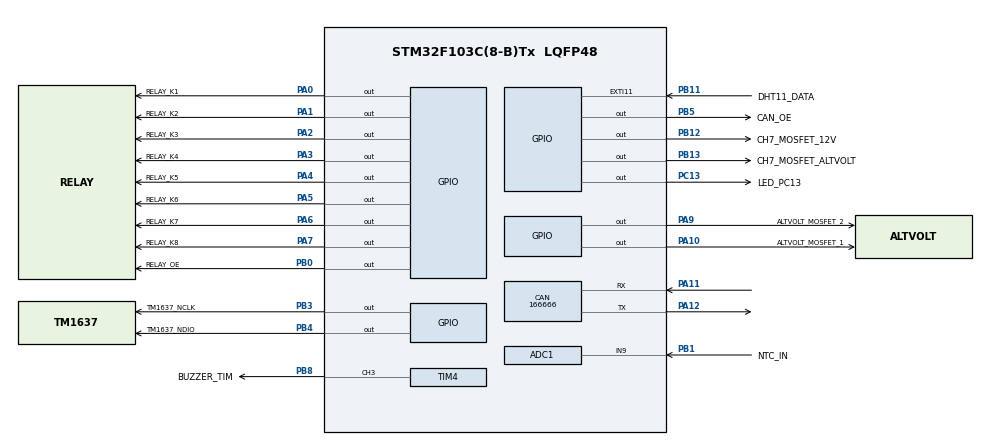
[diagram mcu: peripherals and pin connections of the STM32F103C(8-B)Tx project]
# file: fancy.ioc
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ADC1.Channel-0\#ChannelRegularConversion=ADC_CHANNEL_9
ADC1.Channel-1\#ChannelRegularConversion=ADC_CHANNEL_TEMPSENSOR
ADC1.Channel-3\#ChannelRegularConversion=ADC_CHANNEL_VREFINT
ADC1.NbrOfConversion=3
ADC1.NbrOfConversionFlag=1
ADC1.Rank-0\#ChannelRegularConversion=1
ADC1.Rank-1\#ChannelRegularConversion=2
ADC1.Rank-3\#ChannelRegularConversion=3
ADC1.SamplingTime-0\#ChannelRegularConversion=ADC_SAMPLETIME_13CYCLES_5
ADC1.SamplingTime-1\#ChannelRegularConversion=ADC_SAMPLETIME_13CYCLES_5
ADC1.SamplingTime-3\#ChannelRegularConversion=ADC_SAMPLETIME_13CYCLES_5
ADC1.master=1
CAN.CalculateBaudRate=166666
CAN.CalculateTimeBit=6000
CAN.CalculateTimeQuantum=2000.0
Dma.ADC1.0.Direction=DMA_PERIPH_TO_MEMORY
Dma.ADC1.0.Instance=DMA1_Channel1
Dma.ADC1.0.MemDataAlignment=DMA_MDATAALIGN_HALFWORD
Dma.ADC1.0.MemInc=DMA_MINC_ENABLE
Dma.ADC1.0.Mode=DMA_NORMAL
Dma.ADC1.0.PeriphDataAlignment=DMA_PDATAALIGN_HALFWORD
Dma.ADC1.0.PeriphInc=DMA_PINC_DISABLE
Dma.ADC1.0.Priority=DMA_PRIORITY_LOW
Dma.Request0=ADC1
Mcu.Family=STM32F1
Mcu.Name=STM32F103C(8-B)Tx
Mcu.Package=LQFP48
NVIC.ADC1_2_IRQn=true\:0\:0\:false\:false\:true\:true\:true\:true
NVIC.DMA1_Channel1_IRQn=true\:0\:0\:false\:false\:true\:false\:true\:true
NVIC.EXTI15_10_IRQn=true\:0\:0\:false\:false\:true\:true\:true\:true
NVIC.PriorityGroup=NVIC_PRIORITYGROUP_4
PA0-WKUP.GPIO_Label=RELAY_K1
PA0-WKUP.Signal=GPIO_Output
PA1.GPIO_Label=RELAY_K2
PA1.Signal=GPIO_Output
PA10.GPIO_Label=ALTVOLT_MOSFET_1
PA10.Signal=GPIO_Output
PA11.Mode=CAN_Activate
PA11.Signal=CAN_RX
PA12.Mode=CAN_Activate
PA12.Signal=CAN_TX
PA13.Mode=Serial_Wire
PA13.Signal=SYS_JTMS-SWDIO
PA14.Mode=Serial_Wire
PA14.Signal=SYS_JTCK-SWCLK
PA2.GPIO_Label=RELAY_K3
PA2.Signal=GPIO_Output
PA3.GPIO_Label=RELAY_K4
PA3.Signal=GPIO_Output
PA4.GPIO_Label=RELAY_K5
PA4.Signal=GPIO_Output
PA5.GPIO_Label=RELAY_K6
PA5.Signal=GPIO_Output
PA6.GPIO_Label=RELAY_K7
PA6.Signal=GPIO_Output
PA7.GPIO_Label=RELAY_K8
PA7.Signal=GPIO_Output
PA9.GPIO_Label=ALTVOLT_MOSFET_2
PA9.Signal=GPIO_Output
PB0.GPIO_Label=RELAY_OE
PB0.Signal=GPIO_Output
PB1.GPIO_Label=NTC_IN
PB1.Signal=ADCx_IN9
PB11.GPIO_Label=DHT11_DATA
PB11.GPIO_ModeDefaultEXTI=GPIO_MODE_IT_RISING_FALLING
PB11.Signal=GPXTI11
PB12.GPIO_Label=CH7_MOSFET_12V
PB12.PinState=GPIO_PIN_SET
PB12.Signal=GPIO_Output
PB13.GPIO_Label=CH7_MOSFET_ALTVOLT
PB13.Signal=GPIO_Output
PB3.GPIO_Label=TM1637_NCLK
PB3.Signal=GPIO_Output
PB4.GPIO_Label=TM1637_NDIO
PB4.Signal=GPIO_Output
PB5.GPIO_Label=CAN_OE
PB5.Signal=GPIO_Output
PB8.GPIO_Label=BUZZER_TIM
PB8.Signal=S_TIM4_CH3
PC13-TAMPER-RTC.GPIO_Label=LED_PC13
PC13-TAMPER-RTC.GPIO_ModeDefaultOutputPP=GPIO_MODE_OUTPUT_OD
PC13-TAMPER-RTC.GPIO_PuPd=GPIO_NOPULL
PC13-TAMPER-RTC.PinState=GPIO_PIN_SET
PC13-TAMPER-RTC.Signal=GPIO_Output
ProjectManager.HeapSize=0x200
ProjectManager.StackSize=0x400
ProjectManager.TargetToolchain=STM32CubeIDE
RCC.APB1Freq_Value=8000000
RCC.APB2Freq_Value=8000000
SH.ADCx_IN9.0=ADC1_IN9,IN9
SH.S_TIM4_CH3.0=TIM4_CH3,PWM Generation3 CH3
TIM4.Channel-PWM\ Generation3\ CH3=TIM_CHANNEL_3
VP_ADC1_TempSens_Input.Mode=IN-TempSens
VP_ADC1_Vref_Input.Mode=IN-Vrefint
VP_TIM1_VS_ClockSourceINT.Mode=Internal
board=custom

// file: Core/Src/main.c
/* USER CODE BEGIN Header */
/**
  ******************************************************************************
  * @file           : main.c
  * @brief          : Main program body
  ******************************************************************************
  * @attention
  *
  * Copyright (c) 2024 STMicroelectronics.
  * All rights reserved.
  *
  * This software is licensed under terms that can be found in the LICENSE file
  * in the root directory of this software component.
  * If no LICENSE file comes with this software, it is provided AS-IS.
  *
  ******************************************************************************
  */
/* USER CODE END Header */
#include "main.h"

/* USER CODE BEGIN Includes */

#include "fancy.h"

/* USER CODE END Includes */

ADC_HandleTypeDef hadc1;
DMA_HandleTypeDef hdma_adc1;

CAN_HandleTypeDef hcan;

TIM_HandleTypeDef htim1;
TIM_HandleTypeDef htim4;

void SystemClock_Config(void);
static void MX_GPIO_Init(void);
static void MX_DMA_Init(void);
static void MX_CAN_Init(void);
static void MX_TIM1_Init(void);
static void MX_TIM4_Init(void);
static void MX_ADC1_Init(void);

int main(void)
{

  /* MCU Configuration--------------------------------------------------------*/

  /* Reset of all peripherals, Initializes the Flash interface and the Systick. */
  HAL_Init();

  /* Configure the system clock */
  SystemClock_Config();

  /* Initialize all configured peripherals */
  MX_GPIO_Init();
  MX_DMA_Init();
  MX_CAN_Init();
  MX_TIM1_Init();
  MX_TIM4_Init();
  MX_ADC1_Init();

  /* Infinite loop */
  /* USER CODE BEGIN WHILE */
  fancy(&htim1, &htim4, TIM_CHANNEL_3, &hadc1);
  while (1)
  {
    /* USER CODE END WHILE */

  }
}

void SystemClock_Config(void)
{
  RCC_OscInitTypeDef RCC_OscInitStruct = {0};
  RCC_ClkInitTypeDef RCC_ClkInitStruct = {0};
  RCC_PeriphCLKInitTypeDef PeriphClkInit = {0};

  /** Initializes the RCC Oscillators according to the specified parameters
  * in the RCC_OscInitTypeDef structure.
  */
  RCC_OscInitStruct.OscillatorType = RCC_OSCILLATORTYPE_HSI;
  RCC_OscInitStruct.HSIState = RCC_HSI_ON;
  RCC_OscInitStruct.HSICalibrationValue = RCC_HSICALIBRATION_DEFAULT;
  RCC_OscInitStruct.PLL.PLLState = RCC_PLL_NONE;
  if (HAL_RCC_OscConfig(&RCC_OscInitStruct) != HAL_OK)
  {
    Error_Handler();
  }

  /** Initializes the CPU, AHB and APB buses clocks
  */
  RCC_ClkInitStruct.ClockType = RCC_CLOCKTYPE_HCLK|RCC_CLOCKTYPE_SYSCLK
                              |RCC_CLOCKTYPE_PCLK1|RCC_CLOCKTYPE_PCLK2;
  RCC_ClkInitStruct.SYSCLKSource = RCC_SYSCLKSOURCE_HSI;
  RCC_ClkInitStruct.AHBCLKDivider = RCC_SYSCLK_DIV1;
  RCC_ClkInitStruct.APB1CLKDivider = RCC_HCLK_DIV1;
  RCC_ClkInitStruct.APB2CLKDivider = RCC_HCLK_DIV1;

  if (HAL_RCC_ClockConfig(&RCC_ClkInitStruct, FLASH_LATENCY_0) != HAL_OK)
  {
    Error_Handler();
  }
  PeriphClkInit.PeriphClockSelection = RCC_PERIPHCLK_ADC;
  PeriphClkInit.AdcClockSelection = RCC_ADCPCLK2_DIV2;
  if (HAL_RCCEx_PeriphCLKConfig(&PeriphClkInit) != HAL_OK)
  {
    Error_Handler();
  }
}

static void MX_ADC1_Init(void)
{

  ADC_ChannelConfTypeDef sConfig = {0};

  /** Common config
  */
  hadc1.Instance = ADC1;
  hadc1.Init.ScanConvMode = ADC_SCAN_ENABLE;
  hadc1.Init.ContinuousConvMode = DISABLE;
  hadc1.Init.DiscontinuousConvMode = DISABLE;
  hadc1.Init.ExternalTrigConv = ADC_SOFTWARE_START;
  hadc1.Init.DataAlign = ADC_DATAALIGN_RIGHT;
  hadc1.Init.NbrOfConversion = 3;
  if (HAL_ADC_Init(&hadc1) != HAL_OK)
  {
    Error_Handler();
  }

  /** Configure Regular Channel
  */
  sConfig.Channel = ADC_CHANNEL_9;
  sConfig.Rank = ADC_REGULAR_RANK_1;
  sConfig.SamplingTime = ADC_SAMPLETIME_13CYCLES_5;
  if (HAL_ADC_ConfigChannel(&hadc1, &sConfig) != HAL_OK)
  {
    Error_Handler();
  }

  /** Configure Regular Channel
  */
  sConfig.Channel = ADC_CHANNEL_TEMPSENSOR;
  sConfig.Rank = ADC_REGULAR_RANK_2;
  if (HAL_ADC_ConfigChannel(&hadc1, &sConfig) != HAL_OK)
  {
    Error_Handler();
  }

  /** Configure Regular Channel
  */
  sConfig.Channel = ADC_CHANNEL_VREFINT;
  sConfig.Rank = ADC_REGULAR_RANK_3;
  if (HAL_ADC_ConfigChannel(&hadc1, &sConfig) != HAL_OK)
  {
    Error_Handler();
  }

}

static void MX_CAN_Init(void)
{

  hcan.Instance = CAN1;
  hcan.Init.Prescaler = 16;
  hcan.Init.Mode = CAN_MODE_NORMAL;
  hcan.Init.SyncJumpWidth = CAN_SJW_1TQ;
  hcan.Init.TimeSeg1 = CAN_BS1_1TQ;
  hcan.Init.TimeSeg2 = CAN_BS2_1TQ;
  hcan.Init.TimeTriggeredMode = DISABLE;
  hcan.Init.AutoBusOff = DISABLE;
  hcan.Init.AutoWakeUp = DISABLE;
  hcan.Init.AutoRetransmission = DISABLE;
  hcan.Init.ReceiveFifoLocked = DISABLE;
  hcan.Init.TransmitFifoPriority = DISABLE;
  if (HAL_CAN_Init(&hcan) != HAL_OK)
  {
    Error_Handler();
  }

}

static void MX_TIM1_Init(void)
{

  TIM_ClockConfigTypeDef sClockSourceConfig = {0};
  TIM_MasterConfigTypeDef sMasterConfig = {0};

  htim1.Instance = TIM1;
  htim1.Init.Prescaler = 0;
  htim1.Init.CounterMode = TIM_COUNTERMODE_UP;
  htim1.Init.Period = 65535;
  htim1.Init.ClockDivision = TIM_CLOCKDIVISION_DIV1;
  htim1.Init.RepetitionCounter = 0;
  htim1.Init.AutoReloadPreload = TIM_AUTORELOAD_PRELOAD_DISABLE;
  if (HAL_TIM_Base_Init(&htim1) != HAL_OK)
  {
    Error_Handler();
  }
  sClockSourceConfig.ClockSource = TIM_CLOCKSOURCE_INTERNAL;
  if (HAL_TIM_ConfigClockSource(&htim1, &sClockSourceConfig) != HAL_OK)
  {
    Error_Handler();
  }
  sMasterConfig.MasterOutputTrigger = TIM_TRGO_RESET;
  sMasterConfig.MasterSlaveMode = TIM_MASTERSLAVEMODE_DISABLE;
  if (HAL_TIMEx_MasterConfigSynchronization(&htim1, &sMasterConfig) != HAL_OK)
  {
    Error_Handler();
  }

}

static void MX_TIM4_Init(void)
{

  TIM_MasterConfigTypeDef sMasterConfig = {0};
  TIM_OC_InitTypeDef sConfigOC = {0};

  htim4.Instance = TIM4;
  htim4.Init.Prescaler = 0;
  htim4.Init.CounterMode = TIM_COUNTERMODE_UP;
  htim4.Init.Period = 65535;
  htim4.Init.ClockDivision = TIM_CLOCKDIVISION_DIV1;
  htim4.Init.AutoReloadPreload = TIM_AUTORELOAD_PRELOAD_DISABLE;
  if (HAL_TIM_PWM_Init(&htim4) != HAL_OK)
  {
    Error_Handler();
  }
  sMasterConfig.MasterOutputTrigger = TIM_TRGO_RESET;
  sMasterConfig.MasterSlaveMode = TIM_MASTERSLAVEMODE_DISABLE;
  if (HAL_TIMEx_MasterConfigSynchronization(&htim4, &sMasterConfig) != HAL_OK)
  {
    Error_Handler();
  }
  sConfigOC.OCMode = TIM_OCMODE_PWM1;
  sConfigOC.Pulse = 0;
  sConfigOC.OCPolarity = TIM_OCPOLARITY_HIGH;
  sConfigOC.OCFastMode = TIM_OCFAST_DISABLE;
  if (HAL_TIM_PWM_ConfigChannel(&htim4, &sConfigOC, TIM_CHANNEL_3) != HAL_OK)
  {
    Error_Handler();
  }
  HAL_TIM_MspPostInit(&htim4);

}

static void MX_DMA_Init(void)
{

  /* DMA controller clock enable */
  __HAL_RCC_DMA1_CLK_ENABLE();

  /* DMA interrupt init */
  /* DMA1_Channel1_IRQn interrupt configuration */
  HAL_NVIC_SetPriority(DMA1_Channel1_IRQn, 0, 0);
  HAL_NVIC_EnableIRQ(DMA1_Channel1_IRQn);

}

static void MX_GPIO_Init(void)
{
  GPIO_InitTypeDef GPIO_InitStruct = {0};

  /* GPIO Ports Clock Enable */
  __HAL_RCC_GPIOC_CLK_ENABLE();
  __HAL_RCC_GPIOA_CLK_ENABLE();
  __HAL_RCC_GPIOB_CLK_ENABLE();

  /*Configure GPIO pin Output Level */
  HAL_GPIO_WritePin(LED_PC13_GPIO_Port, LED_PC13_Pin, GPIO_PIN_SET);

  /*Configure GPIO pin Output Level */
  HAL_GPIO_WritePin(GPIOA, RELAY_K1_Pin|RELAY_K2_Pin|RELAY_K3_Pin|RELAY_K4_Pin
                          |RELAY_K5_Pin|RELAY_K6_Pin|RELAY_K7_Pin|RELAY_K8_Pin
                          |ALTVOLT_MOSFET_2_Pin|ALTVOLT_MOSFET_1_Pin, GPIO_PIN_RESET);

  /*Configure GPIO pin Output Level */
  HAL_GPIO_WritePin(GPIOB, RELAY_OE_Pin|CH7_MOSFET_ALTVOLT_Pin|TM1637_NCLK_Pin|TM1637_NDIO_Pin
                          |CAN_OE_Pin, GPIO_PIN_RESET);

  /*Configure GPIO pin Output Level */
  HAL_GPIO_WritePin(CH7_MOSFET_12V_GPIO_Port, CH7_MOSFET_12V_Pin, GPIO_PIN_SET);

  /*Configure GPIO pin : LED_PC13_Pin */
  GPIO_InitStruct.Pin = LED_PC13_Pin;
  GPIO_InitStruct.Mode = GPIO_MODE_OUTPUT_OD;
  GPIO_InitStruct.Pull = GPIO_NOPULL;
  GPIO_InitStruct.Speed = GPIO_SPEED_FREQ_LOW;
  HAL_GPIO_Init(LED_PC13_GPIO_Port, &GPIO_InitStruct);

  /*Configure GPIO pins : RELAY_K1_Pin RELAY_K2_Pin RELAY_K3_Pin RELAY_K4_Pin
                           RELAY_K5_Pin RELAY_K6_Pin RELAY_K7_Pin RELAY_K8_Pin
                           ALTVOLT_MOSFET_2_Pin ALTVOLT_MOSFET_1_Pin */
  GPIO_InitStruct.Pin = RELAY_K1_Pin|RELAY_K2_Pin|RELAY_K3_Pin|RELAY_K4_Pin
                          |RELAY_K5_Pin|RELAY_K6_Pin|RELAY_K7_Pin|RELAY_K8_Pin
                          |ALTVOLT_MOSFET_2_Pin|ALTVOLT_MOSFET_1_Pin;
  GPIO_InitStruct.Mode = GPIO_MODE_OUTPUT_PP;
  GPIO_InitStruct.Pull = GPIO_NOPULL;
  GPIO_InitStruct.Speed = GPIO_SPEED_FREQ_LOW;
  HAL_GPIO_Init(GPIOA, &GPIO_InitStruct);

  /*Configure GPIO pins : RELAY_OE_Pin CH7_MOSFET_12V_Pin CH7_MOSFET_ALTVOLT_Pin TM1637_NCLK_Pin
                           TM1637_NDIO_Pin CAN_OE_Pin */
  GPIO_InitStruct.Pin = RELAY_OE_Pin|CH7_MOSFET_12V_Pin|CH7_MOSFET_ALTVOLT_Pin|TM1637_NCLK_Pin
                          |TM1637_NDIO_Pin|CAN_OE_Pin;
  GPIO_InitStruct.Mode = GPIO_MODE_OUTPUT_PP;
  GPIO_InitStruct.Pull = GPIO_NOPULL;
  GPIO_InitStruct.Speed = GPIO_SPEED_FREQ_LOW;
  HAL_GPIO_Init(GPIOB, &GPIO_InitStruct);

  /*Configure GPIO pin : DHT11_DATA_Pin */
  GPIO_InitStruct.Pin = DHT11_DATA_Pin;
  GPIO_InitStruct.Mode = GPIO_MODE_IT_RISING_FALLING;
  GPIO_InitStruct.Pull = GPIO_NOPULL;
  HAL_GPIO_Init(DHT11_DATA_GPIO_Port, &GPIO_InitStruct);

  /* EXTI interrupt init*/
  HAL_NVIC_SetPriority(EXTI15_10_IRQn, 0, 0);
  HAL_NVIC_EnableIRQ(EXTI15_10_IRQn);

}

void Error_Handler(void)
{
  __disable_irq();
  while (1)
  {
  }
}
